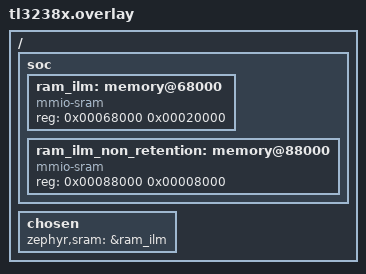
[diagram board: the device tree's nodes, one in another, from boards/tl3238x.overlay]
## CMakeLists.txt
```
#
#    Copyright (c) 2023-2024 Project CHIP Authors
#
#    Licensed under the Apache License, Version 2.0 (the "License");
#    you may not use this file except in compliance with the License.
#    You may obtain a copy of the License at
#
#        http://www.apache.org/licenses/LICENSE-2.0
#
#    Unless required by applicable law or agreed to in writing, software
#    distributed under the License is distributed on an "AS IS" BASIS,
#    WITHOUT WARRANTIES OR CONDITIONS OF ANY KIND, either express or implied.
#    See the License for the specific language governing permissions and
#    limitations under the License.
#

cmake_minimum_required(VERSION 3.20)

get_filename_component(CHIP_ROOT ${CMAKE_CURRENT_SOURCE_DIR}/third_party/connectedhomeip REALPATH)
get_filename_component(TELINK_COMMON ${CHIP_ROOT}/examples/platform/telink REALPATH)
get_filename_component(GEN_DIR ${CHIP_ROOT}/zzz_generated/ REALPATH)

include(${TELINK_COMMON}/common.cmake)
include(${CHIP_ROOT}/config/telink/app/enable-gnu-std.cmake)
include(${CHIP_ROOT}/src/app/chip_data_model.cmake)

project(chip-telink-lock-example)

target_include_directories(app PRIVATE
                           include
                           ${GEN_DIR}/app-common
                           ${GEN_DIR}/lock-app
                           ${TELINK_COMMON}/common/include
                           ${TELINK_COMMON}/util/include
                           ${TELINK_COMMON}/app/include
                           ${TELINK_COMMON}/zephyr_ext)

target_sources(app PRIVATE
               src/AppTask.cpp
               src/AliroDelegate.cpp
               src/ZclCallbacks.cpp
               src/LockManager.cpp
               src/LockSettingsStorage.cpp
               ${CHIP_ROOT}/src/app/persistence/DeferredAttributePersistenceProvider.cpp
               ${TELINK_COMMON}/common/src/mainCommon.cpp
               ${TELINK_COMMON}/common/src/AppTaskCommon.cpp
               ${TELINK_COMMON}/util/src/LEDManager.cpp
               ${TELINK_COMMON}/util/src/ButtonManager.cpp
               ${TELINK_COMMON}/util/src/ThreadUtil.cpp
               ${TELINK_COMMON}/util/src/PWMManager.cpp
               ${TELINK_COMMON}/zephyr_ext/zephyr_key_matrix.c
               ${TELINK_COMMON}/zephyr_ext/zephyr_key_pool.c
               ${TELINK_COMMON}/zephyr_ext/zephyr_led_pool.c
               ${TELINK_COMMON}/zephyr_ext/zephyr_pwm_pool.c
               ${TELINK_COMMON}/zephyr_ext/zephyr_ws2812.c)

chip_configure_data_model(app
    ZAP_FILE ${CMAKE_CURRENT_SOURCE_DIR}/../lock-common/lock-app.zap
)

if(CONFIG_BOOTLOADER_MCUBOOT)
  target_sources(app PRIVATE ${TELINK_COMMON}/util/src/OTAUtil.cpp)
endif()

if(CONFIG_MCUMGR_TRANSPORT_BT)
    zephyr_library_link_libraries(MCUBOOT_BOOTUTIL)
    target_sources(app PRIVATE ${TELINK_COMMON}/util/src/DFUOverSMP.cpp)
endif()
```

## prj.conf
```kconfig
#
#    Copyright (c) 2023-2024 Project CHIP Authors
#
#    Licensed under the Apache License, Version 2.0 (the "License");
#    you may not use this file except in compliance with the License.
#    You may obtain a copy of the License at
#
#        http://www.apache.org/licenses/LICENSE-2.0
#
#    Unless required by applicable law or agreed to in writing, software
#    distributed under the License is distributed on an "AS IS" BASIS,
#    WITHOUT WARRANTIES OR CONDITIONS OF ANY KIND, either express or implied.
#    See the License for the specific language governing permissions and
#    limitations under the License.
#

# This sample uses Kconfig.defaults to set options common for all
# samples. This file should contain only options specific for this sample
# or overrides of default values.

# Enable CHIP
CONFIG_CHIP=y
CONFIG_STD_CPP17=y

# 32774 == 0x8006 (example lock-app)
CONFIG_CHIP_DEVICE_PRODUCT_ID=32774

# Bluetooth Low Energy configuration
CONFIG_BT_DEVICE_NAME="TelinkLock"

# Disable Matter OTA DFU
CONFIG_CHIP_OTA_REQUESTOR=n
CONFIG_CHIP_DEVICE_SOFTWARE_VERSION=1

# Disable CHIP shell support
CONFIG_CHIP_LIB_SHELL=n

# Disable factory data support
CONFIG_CHIP_FACTORY_DATA=n
CONFIG_CHIP_FACTORY_DATA_BUILD=n
CONFIG_CHIP_FACTORY_DATA_MERGE_WITH_FIRMWARE=n

# Enable Power Management
CONFIG_PM=y

#ICD SETTING INFO
CONFIG_CHIP_ICD_SLOW_POLL_INTERVAL=7500
CONFIG_CHIP_ICD_FAST_POLLING_INTERVAL=200
CONFIG_CHIP_ICD_ACTIVE_MODE_THRESHOLD=300
CONFIG_CHIP_ICD_IDLE_MODE_DURATION=900

# open seucre programming , need to open CONFIG_CHIP_FACTORY_DATA and CONFIG_CHIP_CERTIFICATION_DECLARATION_STORAGE
# init should be n
CONFIG_SECURE_PROGRAMMING=n

# Enable CHIP-ID via ble
CONFIG_EXPOSE_CHIP_ID_VIA_BLE=n

# Enable Deferred Store Attribute
CONFIG_DEFERRED_ATTR_STORAGE=n

# CONFIG_MCUBOOT_SIGNATURE_KEY_FILE="bootloader/mcuboot/ecdsa_private_key.pem"
```

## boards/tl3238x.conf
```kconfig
# The TL3238x controller library used by this build does not provide the
# low-power symbols required by the generic Telink lock application.
CONFIG_PM=n

# Preserve the MTD role used by the sleepy lock configuration without PM.
CONFIG_CHIP_THREAD_DEVICE_ROLE_END_DEVICE=y

# TL3238x resource profile. Keep the standard lock data model while sizing
# protocol pools for the available SRAM.
CONFIG_CHIP_PERSISTENT_SUBSCRIPTIONS=n
CONFIG_CHIP_MAX_FABRICS=2

CONFIG_TL_BLE_CTRL_THREAD_STACK_SIZE=1536
CONFIG_MAIN_STACK_SIZE=3560
CONFIG_SYSTEM_WORKQUEUE_STACK_SIZE=1024
CONFIG_OPENTHREAD_THREAD_STACK_SIZE=2048

CONFIG_OPENTHREAD_NUM_MESSAGE_BUFFERS=32
CONFIG_NET_PKT_RX_COUNT=4
CONFIG_NET_PKT_TX_COUNT=4
CONFIG_NET_BUF_RX_COUNT=8
CONFIG_NET_BUF_TX_COUNT=12

CONFIG_NVS_LOOKUP_CACHE_SIZE=128
CONFIG_SETTINGS_NVS_NAME_CACHE_SIZE=64
CONFIG_SETTINGS_NVS_SECTOR_COUNT=2
```

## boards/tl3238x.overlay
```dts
/ {
	soc {
		/delete-node/ memory@68000;
		/delete-node/ memory@80000;

		ram_ilm: memory@68000 {
			compatible = "mmio-sram";
			reg = <0x00068000 0x00020000>;
		};

		ram_ilm_non_retention: memory@88000 {
			compatible = "mmio-sram";
			reg = <0x00088000 0x00008000>;
		};
	};

	chosen {
		zephyr,sram = &ram_ilm;
	};
};
```

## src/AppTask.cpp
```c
/*
 *
 *    Copyright (c) 2023-2024 Project CHIP Authors
 *    All rights reserved.
 *
 *    Licensed under the Apache License, Version 2.0 (the "License");
 *    you may not use this file except in compliance with the License.
 *    You may obtain a copy of the License at
 *
 *        http://www.apache.org/licenses/LICENSE-2.0
 *
 *    Unless required by applicable law or agreed to in writing, software
 *    distributed under the License is distributed on an "AS IS" BASIS,
 *    WITHOUT WARRANTIES OR CONDITIONS OF ANY KIND, either express or implied.
 *    See the License for the specific language governing permissions and
 *    limitations under the License.
 */

#include "AppTask.h"
#include "AliroDelegate.h"
#include "ButtonManager.h"
#include "LEDManager.h"
#include <LockManager.h>
#include <app-common/zap-generated/attributes/Accessors.h>
#include <app/data-model/Nullable.h>
#include <app/server/Server.h>
#include <credentials/FabricTable.h>

LOG_MODULE_DECLARE(app, CONFIG_CHIP_APP_LOG_LEVEL);

using namespace ::chip::app::Clusters::DoorLock;
using namespace chip;
using namespace chip::app;
using namespace ::chip::DeviceLayer;
using namespace ::chip::DeviceLayer::Internal;
using namespace TelinkDoorLock::LockInitParams;

AppTask AppTask::sAppTask;

CHIP_ERROR AppTask::Init(void)
{
    SetExampleButtonCallbacks(LockActionEventHandler);
    TEMPORARY_RETURN_IGNORED InitCommonParts();

    LedManager::getInstance().setLed(LedManager::EAppLed_App0, LockMgr().IsLocked());

    chip::app::DataModel::Nullable<chip::app::Clusters::DoorLock::DlLockState> state;
    chip::EndpointId endpointId{ kExampleEndpointId };
    chip::DeviceLayer::PlatformMgr().LockChipStack();
    chip::app::Clusters::DoorLock::Attributes::LockState::Get(endpointId, state);

    uint8_t numberOfCredentialsPerUser = 0;
    if (!DoorLockServer::Instance().GetNumberOfCredentialsSupportedPerUser(endpointId, numberOfCredentialsPerUser))
    {
        ChipLogError(Zcl,
                     "Unable to get number of credentials supported per user when initializing lock endpoint, defaulting to %d "
                     "[endpointId=%d]",
                     APP_DEFAULT_CREDENTIAL_COUNT, endpointId);
        numberOfCredentialsPerUser = APP_DEFAULT_CREDENTIAL_COUNT;
    }

    uint16_t numberOfUsers = 0;
    if (!DoorLockServer::Instance().GetNumberOfUserSupported(endpointId, numberOfUsers))
    {
        ChipLogError(Zcl,
                     "Unable to get number of supported users when initializing lock endpoint, defaulting to %d [endpointId=%d]",
                     APP_DEFAULT_USERS_COUNT, endpointId);
        numberOfUsers = APP_DEFAULT_USERS_COUNT;
    }

    uint8_t numberOfWeekdaySchedulesPerUser = 0;
    if (!DoorLockServer::Instance().GetNumberOfWeekDaySchedulesPerUserSupported(endpointId, numberOfWeekdaySchedulesPerUser))
    {
        ChipLogError(
            Zcl,
            "Unable to get number of supported weekday schedules when initializing lock endpoint, defaulting to %d [endpointId=%d]",
            APP_DEFAULT_WEEKDAY_SCHEDULE_PER_USER_COUNT, endpointId);
        numberOfWeekdaySchedulesPerUser = APP_DEFAULT_WEEKDAY_SCHEDULE_PER_USER_COUNT;
    }

    uint8_t numberOfYeardaySchedulesPerUser = 0;
    if (!DoorLockServer::Instance().GetNumberOfYearDaySchedulesPerUserSupported(endpointId, numberOfYeardaySchedulesPerUser))
    {
        ChipLogError(
            Zcl,
            "Unable to get number of supported yearday schedules when initializing lock endpoint, defaulting to %d [endpointId=%d]",
            APP_DEFAULT_YEARDAY_SCHEDULE_PER_USER_COUNT, endpointId);
        numberOfYeardaySchedulesPerUser = APP_DEFAULT_YEARDAY_SCHEDULE_PER_USER_COUNT;
    }

    uint8_t numberOfHolidaySchedules = 0;
    if (!DoorLockServer::Instance().GetNumberOfHolidaySchedulesSupported(endpointId, numberOfHolidaySchedules))
    {
        ChipLogError(
            Zcl,
            "Unable to get number of supported holiday schedules when initializing lock endpoint, defaulting to %d [endpointId=%d]",
            APP_DEFAULT_HOLYDAY_SCHEDULE_PER_USER_COUNT, endpointId);
        numberOfHolidaySchedules = APP_DEFAULT_HOLYDAY_SCHEDULE_PER_USER_COUNT;
    }

    chip::DeviceLayer::PlatformMgr().UnlockChipStack();

    CHIP_ERROR err = CHIP_NO_ERROR;

    err = LockMgr().Init(state,
                         ParamBuilder()
                             .SetNumberOfUsers(numberOfUsers)
                             .SetNumberOfCredentialsPerUser(numberOfCredentialsPerUser)
                             .SetNumberOfWeekdaySchedulesPerUser(numberOfWeekdaySchedulesPerUser)
                             .SetNumberOfYeardaySchedulesPerUser(numberOfYeardaySchedulesPerUser)
                             .SetNumberOfHolidaySchedules(numberOfHolidaySchedules)
                             .GetLockParam(),
                         LockStateChanged);

    if (err != CHIP_NO_ERROR)
    {
        LOG_ERR("LockMgr().Init() failed");
        return err;
    }

    // Disable auto-relock time feature.
    DoorLockServer::Instance().SetAutoRelockTime(kExampleEndpointId, 0);

    // Register a Door Lock delegate to handle Aliro provisioning attributes/commands.
    DoorLockServer::Instance().SetDelegate(kExampleEndpointId, &AliroDelegate::GetInstance());

    return CHIP_NO_ERROR;
}

/* This is a button handler only */
void AppTask::LockActionEventHandler(AppEvent * aEvent)
{
    switch (LockMgr().getLockState())
    {
    case LockManager::kState_NotFulyLocked:
    case LockManager::kState_LockCompleted:
        LockMgr().LockAction(AppEvent::kEventType_DeviceAction, LockManager::UNLOCK_ACTION, LockManager::OperationSource::kButton,
                             kExampleEndpointId);
        break;
    case LockManager::kState_UnlockCompleted:
        LockMgr().LockAction(AppEvent::kEventType_DeviceAction, LockManager::LOCK_ACTION, LockManager::OperationSource::kButton,
                             kExampleEndpointId);
        break;
    default:
        LOG_INF("Lock is in intermediate state, ignoring button");
        break;
    }
}

void AppTask::LockStateChanged(LockManager::State_t state)
{
    switch (state)
    {
    case LockManager::State_t::kState_LockInitiated:
        LOG_INF("Callback: Lock action initiated");
        LedManager::getInstance().setLed(LedManager::EAppLed_App0, 50, 50);
        break;
    case LockManager::State_t::kState_LockCompleted:
        LOG_INF("Callback: Lock action completed");
        LedManager::getInstance().setLed(LedManager::EAppLed_App0, true);
        break;
    case LockManager::State_t::kState_UnlockInitiated:
        LOG_INF("Callback: Unlock action initiated");
        LedManager::getInstance().setLed(LedManager::EAppLed_App0, 50, 50);
        break;
    case LockManager::State_t::kState_UnlockCompleted:
        LOG_INF("Callback: Unlock action completed");
        LedManager::getInstance().setLed(LedManager::EAppLed_App0, false);
        break;
    case LockManager::State_t::kState_UnlatchInitiated:
        LOG_INF("Callback: Unbolt action initiated");
        LedManager::getInstance().setLed(LedManager::EAppLed_App0, 75, 25);
        break;
    case LockManager::State_t::kState_UnlatchCompleted:
        LOG_INF("Callback: Unbolt action completed");
        LedManager::getInstance().setLed(LedManager::EAppLed_App0, 25, 75);
        break;
    case LockManager::State_t::kState_NotFulyLocked:
        LOG_INF("Callback: Lock not fully locked. Unexpected state");
        LedManager::getInstance().setLed(LedManager::EAppLed_App0, 10, 90);
        break;
    }
}

void AppTask::LockJammedEventHandler(void)
{
    AppEvent event;

    event.Type               = AppEvent::kEventType_Button;
    event.ButtonEvent.Action = kButtonPushEvent;
    event.Handler            = LockJammedActionHandler;
    GetAppTask().PostEvent(&event);
}

void AppTask::LockJammedActionHandler(AppEvent * aEvent)
{
    LOG_INF("Sending a lock jammed event");

    /* Generating Door Lock Jammed event */
    DoorLockServer::Instance().SendLockAlarmEvent(kExampleEndpointId, AlarmCodeEnum::kLockJammed);
}

void AppTask::LockStateEventHandler(void)
{
    AppEvent event;

    event.Type               = AppEvent::kEventType_Button;
    event.ButtonEvent.Action = kButtonPushEvent;
    event.Handler            = LockStateActionHandler;
    GetAppTask().PostEvent(&event);
}

void AppTask::LockStateActionHandler(AppEvent * aEvent)
{
    LOG_INF("Sending a lock state event");

    // This code was written for testing purpose only
    // For real door status the level detection may be used instead of pulse
    static DoorStateEnum mDoorState = DoorStateEnum::kDoorOpen;
    if (mDoorState == DoorStateEnum::kDoorOpen)
    {
        mDoorState = DoorStateEnum::kDoorClosed;
    }
    else
    {
        mDoorState = DoorStateEnum::kDoorOpen;
    }

    /* Generating Door Lock Status event */
    DoorLockServer::Instance().SetDoorState(kExampleEndpointId, mDoorState);
}

void AppTask::LinkButtons(ButtonManager & buttonManager)
{
    buttonManager.addCallback(FactoryResetButtonEventHandler, 0, true);
    buttonManager.addCallback(ExampleActionButtonEventHandler, 1, true);
    buttonManager.addCallback(LockJammedEventHandler, 2, true);
    buttonManager.addCallback(LockStateEventHandler, 3, true);
}

void AppTask::LinkLeds(LedManager & ledManager)
{
#if CONFIG_CHIP_ENABLE_APPLICATION_STATUS_LED
    ledManager.linkLed(LedManager::EAppLed_Status, 0);
    ledManager.linkLed(LedManager::EAppLed_App0, 1);
#else
    ledManager.linkLed(LedManager::EAppLed_App0, 0);
#endif // CONFIG_CHIP_ENABLE_APPLICATION_STATUS_LED
}
```
